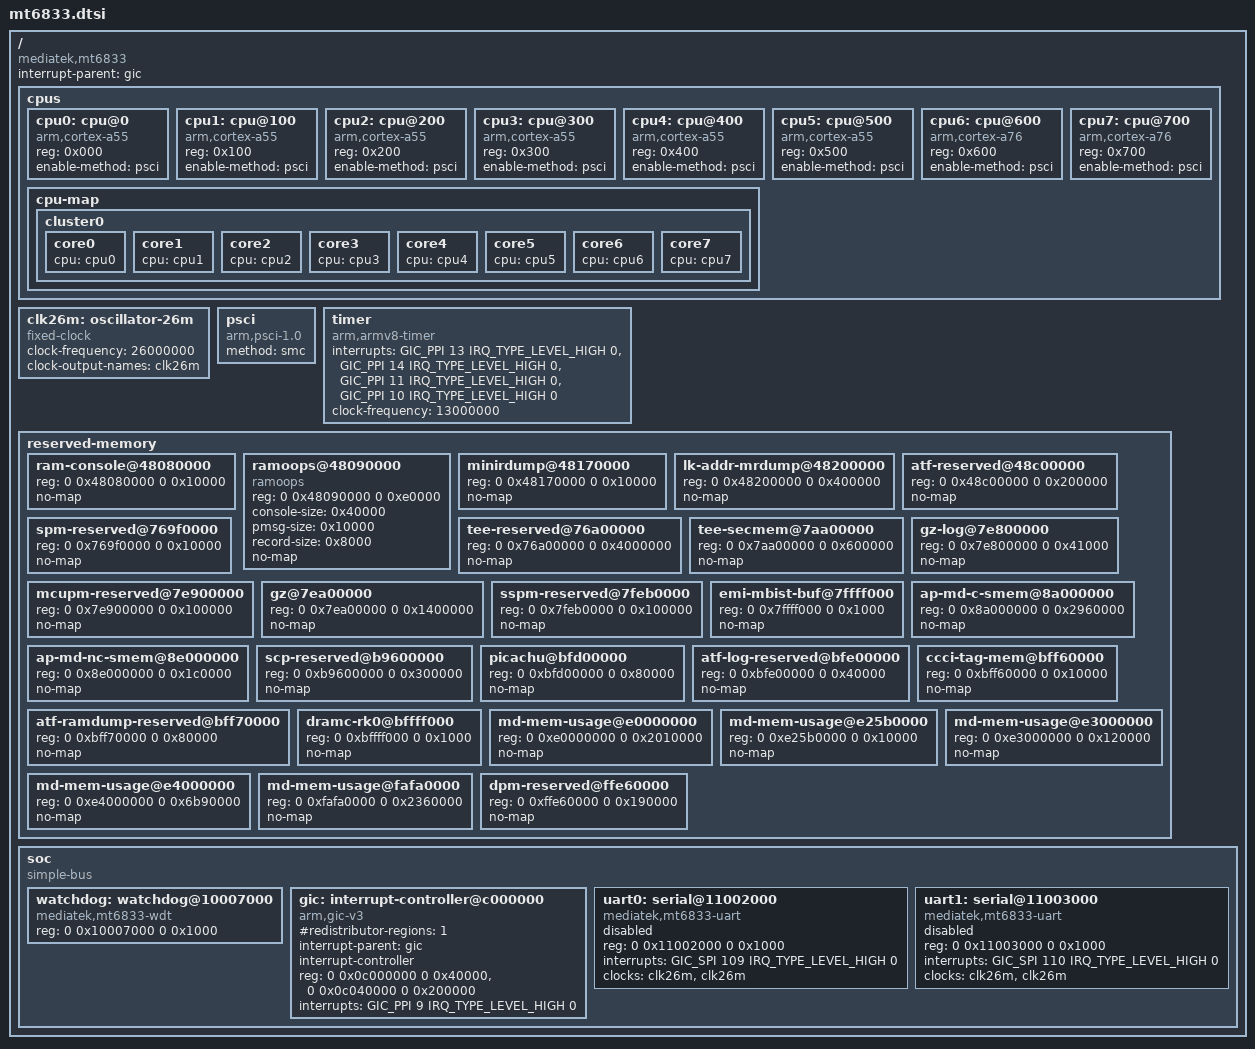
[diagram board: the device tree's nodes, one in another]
// SPDX-License-Identifier: (GPL-2.0-only OR MIT)
/*
 * MediaTek MT6833 (Dimensity 700) - minimal bring-up SoC description.
 * Register map and interrupts taken from the stock A226BXXSBDZC3 device tree.
 */

#include <dt-bindings/interrupt-controller/arm-gic.h>
#include <dt-bindings/interrupt-controller/irq.h>

/ {
	compatible = "mediatek,mt6833";
	interrupt-parent = <&gic>;
	#address-cells = <2>;
	#size-cells = <2>;

	cpus {
		#address-cells = <1>;
		#size-cells = <0>;

		cpu0: cpu@0 {
			device_type = "cpu";
			compatible = "arm,cortex-a55";
			reg = <0x000>;
			enable-method = "psci";
		};

		cpu1: cpu@100 {
			device_type = "cpu";
			compatible = "arm,cortex-a55";
			reg = <0x100>;
			enable-method = "psci";
		};

		cpu2: cpu@200 {
			device_type = "cpu";
			compatible = "arm,cortex-a55";
			reg = <0x200>;
			enable-method = "psci";
		};

		cpu3: cpu@300 {
			device_type = "cpu";
			compatible = "arm,cortex-a55";
			reg = <0x300>;
			enable-method = "psci";
		};

		cpu4: cpu@400 {
			device_type = "cpu";
			compatible = "arm,cortex-a55";
			reg = <0x400>;
			enable-method = "psci";
		};

		cpu5: cpu@500 {
			device_type = "cpu";
			compatible = "arm,cortex-a55";
			reg = <0x500>;
			enable-method = "psci";
		};

		cpu6: cpu@600 {
			device_type = "cpu";
			compatible = "arm,cortex-a76";
			reg = <0x600>;
			enable-method = "psci";
		};

		cpu7: cpu@700 {
			device_type = "cpu";
			compatible = "arm,cortex-a76";
			reg = <0x700>;
			enable-method = "psci";
		};

		cpu-map {
			cluster0 {
				core0 { cpu = <&cpu0>; };
				core1 { cpu = <&cpu1>; };
				core2 { cpu = <&cpu2>; };
				core3 { cpu = <&cpu3>; };
				core4 { cpu = <&cpu4>; };
				core5 { cpu = <&cpu5>; };
				core6 { cpu = <&cpu6>; };
				core7 { cpu = <&cpu7>; };
			};
		};
	};

	clk26m: oscillator-26m {
		compatible = "fixed-clock";
		#clock-cells = <0>;
		clock-frequency = <26000000>;
		clock-output-names = "clk26m";
	};

	psci {
		compatible = "arm,psci-1.0";
		method = "smc";
	};

	timer {
		compatible = "arm,armv8-timer";
		interrupts = <GIC_PPI 13 IRQ_TYPE_LEVEL_HIGH 0>,
			     <GIC_PPI 14 IRQ_TYPE_LEVEL_HIGH 0>,
			     <GIC_PPI 11 IRQ_TYPE_LEVEL_HIGH 0>,
			     <GIC_PPI 10 IRQ_TYPE_LEVEL_HIGH 0>;
		clock-frequency = <13000000>;
	};

	reserved-memory {
		#address-cells = <2>;
		#size-cells = <2>;
		ranges;

		ram-console@48080000 {
			reg = <0 0x48080000 0 0x10000>;
			no-map;
		};

		ramoops@48090000 {
			compatible = "ramoops";
			reg = <0 0x48090000 0 0xe0000>;
			console-size = <0x40000>;
			pmsg-size = <0x10000>;
			record-size = <0x8000>;
			no-map;
		};

		minirdump@48170000 {
			reg = <0 0x48170000 0 0x10000>;
			no-map;
		};

		lk-addr-mrdump@48200000 {
			reg = <0 0x48200000 0 0x400000>;
			no-map;
		};

		atf-reserved@48c00000 {
			reg = <0 0x48c00000 0 0x200000>;
			no-map;
		};

		spm-reserved@769f0000 {
			reg = <0 0x769f0000 0 0x10000>;
			no-map;
		};

		tee-reserved@76a00000 {
			reg = <0 0x76a00000 0 0x4000000>;
			no-map;
		};

		tee-secmem@7aa00000 {
			reg = <0 0x7aa00000 0 0x600000>;
			no-map;
		};

		gz-log@7e800000 {
			reg = <0 0x7e800000 0 0x41000>;
			no-map;
		};

		mcupm-reserved@7e900000 {
			reg = <0 0x7e900000 0 0x100000>;
			no-map;
		};

		gz@7ea00000 {
			reg = <0 0x7ea00000 0 0x1400000>;
			no-map;
		};

		sspm-reserved@7feb0000 {
			reg = <0 0x7feb0000 0 0x100000>;
			no-map;
		};

		emi-mbist-buf@7ffff000 {
			reg = <0 0x7ffff000 0 0x1000>;
			no-map;
		};

		ap-md-c-smem@8a000000 {
			reg = <0 0x8a000000 0 0x2960000>;
			no-map;
		};

		ap-md-nc-smem@8e000000 {
			reg = <0 0x8e000000 0 0x1c0000>;
			no-map;
		};

		scp-reserved@b9600000 {
			reg = <0 0xb9600000 0 0x300000>;
			no-map;
		};

		picachu@bfd00000 {
			reg = <0 0xbfd00000 0 0x80000>;
			no-map;
		};

		atf-log-reserved@bfe00000 {
			reg = <0 0xbfe00000 0 0x40000>;
			no-map;
		};

		ccci-tag-mem@bff60000 {
			reg = <0 0xbff60000 0 0x10000>;
			no-map;
		};

		atf-ramdump-reserved@bff70000 {
			reg = <0 0xbff70000 0 0x80000>;
			no-map;
		};

		dramc-rk0@bffff000 {
			reg = <0 0xbffff000 0 0x1000>;
			no-map;
		};

		md-mem-usage@e0000000 {
			reg = <0 0xe0000000 0 0x2010000>;
			no-map;
		};

		md-mem-usage@e25b0000 {
			reg = <0 0xe25b0000 0 0x10000>;
			no-map;
		};

		md-mem-usage@e3000000 {
			reg = <0 0xe3000000 0 0x120000>;
			no-map;
		};

		md-mem-usage@e4000000 {
			reg = <0 0xe4000000 0 0x6b90000>;
			no-map;
		};

		md-mem-usage@fafa0000 {
			reg = <0 0xfafa0000 0 0x2360000>;
			no-map;
		};

		dpm-reserved@ffe60000 {
			reg = <0 0xffe60000 0 0x190000>;
			no-map;
		};

	};

	soc {
		compatible = "simple-bus";
		#address-cells = <2>;
		#size-cells = <2>;
		ranges;

		watchdog: watchdog@10007000 {
			compatible = "mediatek,mt6833-wdt", "mediatek,mt6589-wdt";
			reg = <0 0x10007000 0 0x1000>;
		};

		gic: interrupt-controller@c000000 {
			compatible = "arm,gic-v3";
			#interrupt-cells = <4>;
			#redistributor-regions = <1>;
			interrupt-parent = <&gic>;
			interrupt-controller;
			reg = <0 0x0c000000 0 0x40000>,
			      <0 0x0c040000 0 0x200000>;
			interrupts = <GIC_PPI 9 IRQ_TYPE_LEVEL_HIGH 0>;
		};

		uart0: serial@11002000 {
			compatible = "mediatek,mt6833-uart", "mediatek,mt6577-uart";
			reg = <0 0x11002000 0 0x1000>;
			interrupts = <GIC_SPI 109 IRQ_TYPE_LEVEL_HIGH 0>;
			clocks = <&clk26m>, <&clk26m>;
			clock-names = "baud", "bus";
			status = "disabled";
		};

		uart1: serial@11003000 {
			compatible = "mediatek,mt6833-uart", "mediatek,mt6577-uart";
			reg = <0 0x11003000 0 0x1000>;
			interrupts = <GIC_SPI 110 IRQ_TYPE_LEVEL_HIGH 0>;
			clocks = <&clk26m>, <&clk26m>;
			clock-names = "baud", "bus";
			status = "disabled";
		};
	};
};
